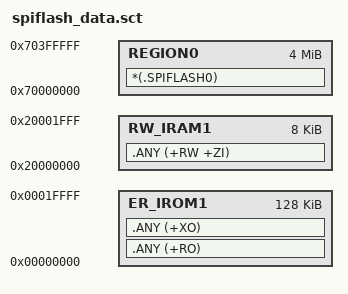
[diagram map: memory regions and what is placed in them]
; *************************************************************
; *** Scatter-Loading Description File generated by uVision ***
; *************************************************************
LR_IROM1 0x00000000 0x20000  {    ; load region size_region
  ER_IROM1 0x00000000 0x20000  {  ; load address = execution address
   .ANY (+RO)
   .ANY (+XO)
  }
  RW_IRAM1 0x20000000 0x2000  {  ; RW data
   .ANY (+RW +ZI)
  }
}

LR_SPIFLASH 0xC0000000 0x00400000  {      ; load region size_region
  REGION0 0x70000000 0x00400000  {
    *(.SPIFLASH0)
  }
}

